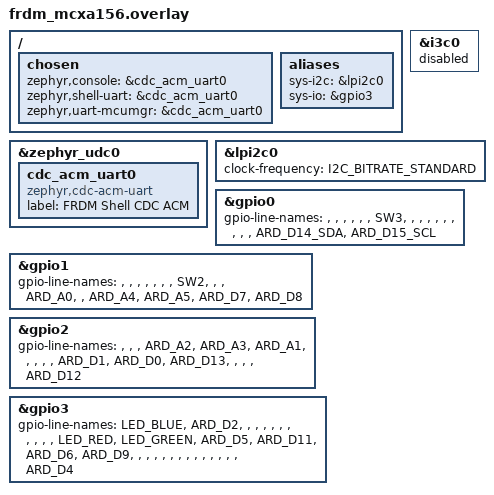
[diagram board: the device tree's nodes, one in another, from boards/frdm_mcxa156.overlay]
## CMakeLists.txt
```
# SPDX-License-Identifier: Apache-2.0

cmake_minimum_required(VERSION 3.20.0)

find_package(Zephyr REQUIRED HINTS $ENV{ZEPHYR_BASE})
project(frdm_shell_bench_tool_cdc)

target_sources(app PRIVATE src/main.c)
```

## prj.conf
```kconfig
# FRDM shell bench tool over USB CDC ACM.
#
# This follows Zephyr's CDC ACM sample/snippet path: create a CDC ACM UART,
# initialize it at boot, and use that UART as the shell backend.

CONFIG_USB_DEVICE_STACK_NEXT=y
CONFIG_CDC_ACM_SERIAL_INITIALIZE_AT_BOOT=y
CONFIG_CDC_ACM_SERIAL_PRODUCT_STRING="FRDM Shell Bench Tool CDC"

CONFIG_SERIAL=y
CONFIG_CONSOLE=y
CONFIG_UART_CONSOLE=y
CONFIG_UART_LINE_CTRL=y
CONFIG_STDOUT_CONSOLE=y

CONFIG_LOG=y
CONFIG_LOG_CMDS=y
CONFIG_USBD_CDC_ACM_LOG_LEVEL_OFF=y
CONFIG_USBD_LOG_LEVEL_OFF=y
CONFIG_UDC_DRIVER_LOG_LEVEL_OFF=y

# Demo module command from modules/module-sample.
CONFIG_COW=y

CONFIG_SHELL=y
CONFIG_SHELL_HELP=y
CONFIG_SHELL_HISTORY=y
CONFIG_SHELL_DEVICE_HELPERS=y
CONFIG_SHELL_BACKEND_SERIAL_CHECK_DTR=y
CONFIG_SHELL_PROMPT_UART="frdm-cdc:~$ "

CONFIG_DEVICE_SHELL=y
CONFIG_DEVICE_DT_METADATA=y

CONFIG_REBOOT=y
CONFIG_KERNEL_SHELL=y
CONFIG_THREAD_MONITOR=y

CONFIG_I2C=y
CONFIG_I2C_SHELL=y

CONFIG_GPIO=y
CONFIG_GPIO_SHELL=y
CONFIG_GPIO_SHELL_INFO_CMD=y
CONFIG_GPIO_SHELL_TOGGLE_CMD=y
CONFIG_GPIO_SHELL_BLINK_CMD=y
```

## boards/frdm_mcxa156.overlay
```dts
/*
 * FRDM-MCXA156 USB CDC shell routing plus friendly shell-facing names.
 */

/ {
	chosen {
		zephyr,console = &cdc_acm_uart0;
		zephyr,shell-uart = &cdc_acm_uart0;
		zephyr,uart-mcumgr = &cdc_acm_uart0;
	};

	aliases {
		sys-i2c = &lpi2c0;
		sys-io = &gpio3;
	};
};

&zephyr_udc0 {
	cdc_acm_uart0: cdc_acm_uart0 {
		compatible = "zephyr,cdc-acm-uart";
		label = "FRDM Shell CDC ACM";
	};
};

/* The Arduino D14/D15 pins share pads with I3C0 on the stock board file. */
&i3c0 {
	status = "disabled";
};

sys_i2c: &lpi2c0 {
	status = "okay";
	clock-frequency = <I2C_BITRATE_STANDARD>;
};

gpio_i2c_header: &gpio0 {
	status = "okay";
	gpio-line-names = "", "", "", "", "", "", "SW3", "", "", "", "", "", "", "", "", "",
			  "ARD_D14_SDA", "ARD_D15_SCL";
};

gpio_arduino_a: &gpio1 {
	status = "okay";
	gpio-line-names = "", "", "", "", "", "", "", "SW2", "", "", "ARD_A0", "",
			  "ARD_A4", "ARD_A5", "ARD_D7", "ARD_D8";
};

gpio_arduino_c: &gpio2 {
	status = "okay";
	gpio-line-names = "", "", "", "ARD_A2", "ARD_A3", "ARD_A1", "", "", "", "",
			  "ARD_D1", "ARD_D0", "ARD_D13", "", "", "", "ARD_D12";
};

sys_io: &gpio3 {
	status = "okay";
	gpio-line-names = "LED_BLUE", "ARD_D2", "", "", "", "", "", "", "", "", "", "",
			  "LED_RED", "LED_GREEN", "ARD_D5", "ARD_D11", "ARD_D6", "ARD_D9",
			  "", "", "", "", "", "", "", "", "", "", "", "", "",
			  "ARD_D4";
};
```

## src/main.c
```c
/*
 * SPDX-License-Identifier: Apache-2.0
 *
 * FRDM shell bench tool over USB CDC ACM.
 *
 * The CDC ACM serial backend, I2C commands, and GPIO commands are enabled by
 * Kconfig/devicetree. There is intentionally no application bus logic here.
 */

#include <zephyr/kernel.h>
#include <zephyr/sys/printk.h>

int main(void)
{
	printk("FRDM CDC shell bench tool ready. Use `help`, `device list`, `i2c`, and `gpio`.\n");

	while (true) {
		k_sleep(K_SECONDS(1));
	}

	return 0;
}
```
